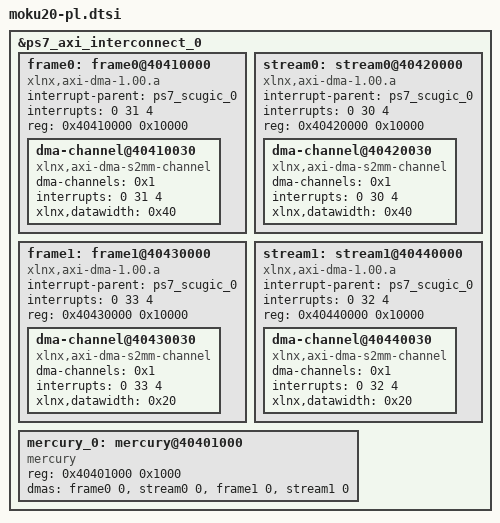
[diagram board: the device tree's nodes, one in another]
/*
 * CAUTION: This file is automatically generated by Xilinx.
 * Version:  
 * Today is: Wed Dec  3 15:57:26 2014
*/

	&ps7_axi_interconnect_0 {
		ranges;
		frame0: frame0@40410000 {
			#dma-cells = <1>;
			compatible = "xlnx,axi-dma-1.00.a";
			interrupt-parent = <&ps7_scugic_0>;
			interrupts = <0 31 4>;
			reg = <0x40410000 0x10000>;
			dma-channel@40410030 {
				compatible = "xlnx,axi-dma-s2mm-channel";
				dma-channels = <0x1>;
				interrupts = <0 31 4>;
				xlnx,datawidth = <0x40>;
			} ;
		} ;
		stream0: stream0@40420000 {
			#dma-cells = <1>;
			compatible = "xlnx,axi-dma-1.00.a";
			interrupt-parent = <&ps7_scugic_0>;
			interrupts = <0 30 4>;
			reg = <0x40420000 0x10000>;
			dma-channel@40420030 {
				compatible = "xlnx,axi-dma-s2mm-channel";
				dma-channels = <0x1>;
				interrupts = <0 30 4>;
				xlnx,datawidth = <0x40>;
			} ;
		} ;
		frame1: frame1@40430000 {
			#dma-cells = <1>;
			compatible = "xlnx,axi-dma-1.00.a";
			interrupt-parent = <&ps7_scugic_0>;
			interrupts = <0 33 4>;
			reg = <0x40430000 0x10000>;
			dma-channel@40430030 {
				compatible = "xlnx,axi-dma-s2mm-channel";
				dma-channels = <0x1>;
				interrupts = <0 33 4>;
				xlnx,datawidth = <0x20>;
			};
		};
		stream1: stream1@40440000 {
			#dma-cells = <1>;
			compatible = "xlnx,axi-dma-1.00.a";
			interrupt-parent = <&ps7_scugic_0>;
			interrupts = <0 32 4>;
			reg = <0x40440000 0x10000>;
			dma-channel@40440030 {
				compatible = "xlnx,axi-dma-s2mm-channel";
				dma-channels = <0x1>;
				interrupts = <0 32 4>;
				xlnx,datawidth = <0x20>;
			};
		};

		mercury_0: mercury@40401000 {
			compatible = "mercury";
			reg = <0x40401000 0x1000>;

			dmas = < &frame0	0
					 &stream0	0
					 &frame1	0
					 &stream1	0>;
			dma-names = "frame0", "stream0", "frame1", "stream1";
		} ;
	} ;
